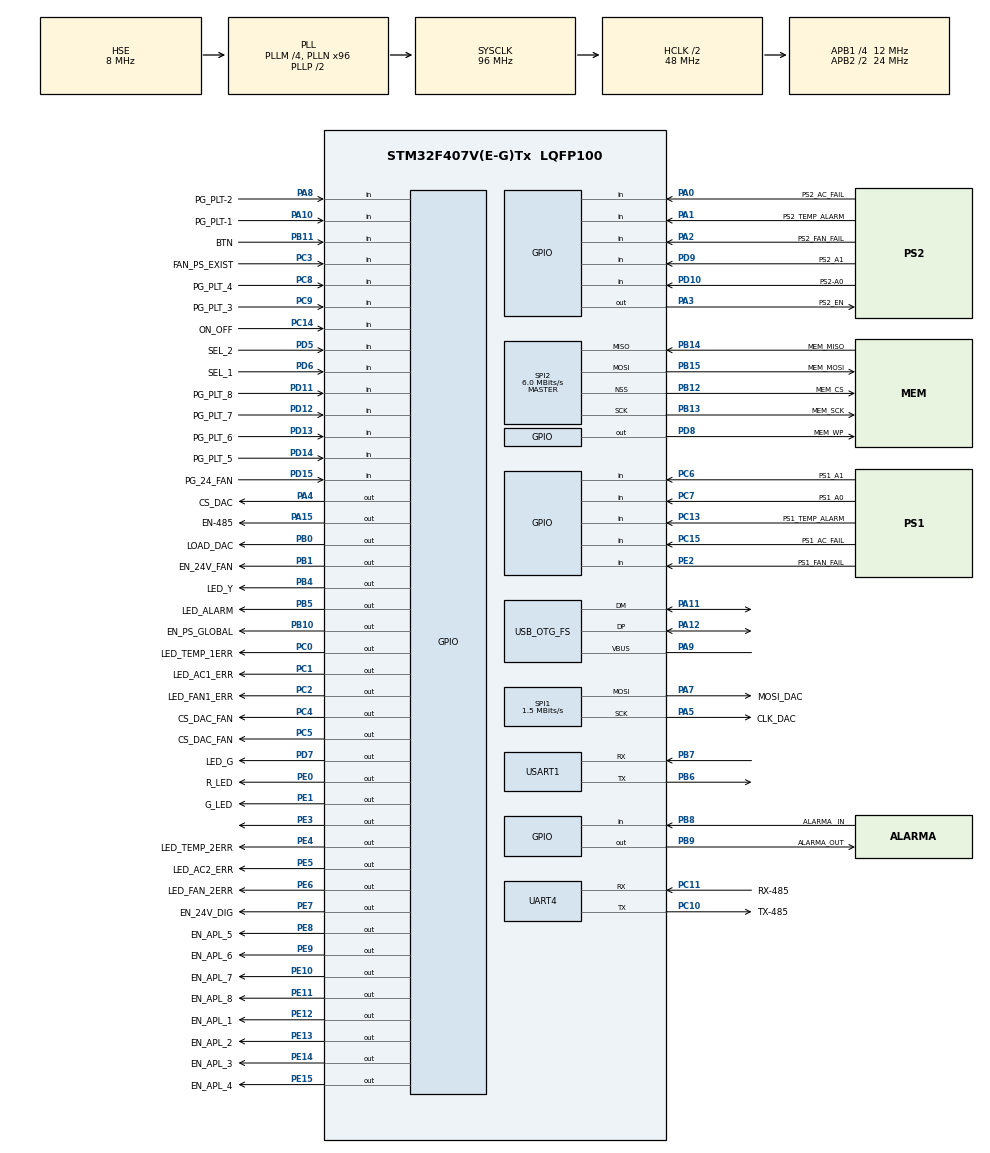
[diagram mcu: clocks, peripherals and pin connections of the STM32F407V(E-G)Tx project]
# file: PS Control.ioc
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Mcu.Family=STM32F4
Mcu.Name=STM32F407V(E-G)Tx
Mcu.Package=LQFP100
NVIC.PriorityGroup=NVIC_PRIORITYGROUP_4
NVIC.UART4_IRQn=true\:0\:0\:false\:false\:true\:true\:true\:true
NVIC.USART1_IRQn=true\:0\:0\:false\:false\:true\:true\:true\:true
PA0-WKUP.GPIO_Label=PS2_AC_FAIL
PA0-WKUP.Signal=GPIO_Input
PA1.GPIO_Label=PS2_TEMP_ALARM
PA1.GPIO_PuPd=GPIO_PULLDOWN
PA1.Signal=GPIO_Input
PA10.GPIO_Label=PG_PLT-1
PA10.GPIO_PuPd=GPIO_PULLUP
PA10.Signal=GPIO_Input
PA11.Mode=Device_Only
PA11.Signal=USB_OTG_FS_DM
PA12.Mode=Device_Only
PA12.Signal=USB_OTG_FS_DP
PA13.Signal=SYS_JTMS-SWDIO
PA14.Signal=SYS_JTCK-SWCLK
PA15.GPIO_Label=EN-485
PA15.GPIO_PuPd=GPIO_PULLDOWN
PA15.Signal=GPIO_Output
PA2.GPIO_Label=PS2_FAN_FAIL
PA2.Signal=GPIO_Input
PA3.GPIO_Label=PS2_EN
PA3.GPIO_PuPd=GPIO_PULLUP
PA3.Signal=GPIO_Output
PA4.GPIO_Label=CS_DAC
PA4.GPIO_PuPd=GPIO_PULLUP
PA4.PinState=GPIO_PIN_SET
PA4.Signal=GPIO_Output
PA5.GPIO_Label=CLK_DAC
PA5.Mode=TX_Only_Simplex_Unidirect_Master
PA5.Signal=SPI1_SCK
PA7.GPIO_Label=MOSI_DAC
PA7.Mode=TX_Only_Simplex_Unidirect_Master
PA7.Signal=SPI1_MOSI
PA8.GPIO_Label=PG_PLT-2
PA8.GPIO_PuPd=GPIO_PULLUP
PA8.Signal=GPIO_Input
PA9.Mode=Activate_VBUS
PA9.Signal=USB_OTG_FS_VBUS
PB0.GPIO_Label=LOAD_DAC
PB0.GPIO_PuPd=GPIO_PULLUP
PB0.PinState=GPIO_PIN_SET
PB0.Signal=GPIO_Output
PB1.GPIO_Label=EN_24V_FAN
PB1.GPIO_PuPd=GPIO_PULLUP
PB1.PinState=GPIO_PIN_SET
PB1.Signal=GPIO_Output
PB10.GPIO_Label=EN_PS_GLOBAL
PB10.GPIO_PuPd=GPIO_PULLUP
PB10.PinState=GPIO_PIN_SET
PB10.Signal=GPIO_Output
PB11.GPIO_Label=BTN
PB11.GPIO_PuPd=GPIO_PULLUP
PB11.Signal=GPIO_Input
PB12.GPIO_Label=MEM_CS
PB12.Mode=NSS_Signal_Hard_Output
PB12.Signal=SPI2_NSS
PB13.GPIO_Label=MEM_SCK
PB13.Mode=Full_Duplex_Master
PB13.Signal=SPI2_SCK
PB14.GPIO_Label=MEM_MISO
PB14.Mode=Full_Duplex_Master
PB14.Signal=SPI2_MISO
PB15.GPIO_Label=MEM_MOSI
PB15.Mode=Full_Duplex_Master
PB15.Signal=SPI2_MOSI
PB3.Signal=SYS_JTDO-SWO
PB4.GPIO_Label=LED_Y
PB4.PinState=GPIO_PIN_SET
PB4.Signal=GPIO_Output
PB5.GPIO_Label=LED_ALARM
PB5.PinState=GPIO_PIN_SET
PB5.Signal=GPIO_Output
PB6.Mode=Asynchronous
PB6.Signal=USART1_TX
PB7.Mode=Asynchronous
PB7.Signal=USART1_RX
PB8.GPIO_Label=ALARMA _IN
PB8.GPIO_PuPd=GPIO_PULLUP
PB8.Signal=GPIO_Input
PB9.GPIO_Label=ALARMA_OUT
PB9.GPIO_PuPd=GPIO_PULLDOWN
PB9.Signal=GPIO_Output
PC0.GPIO_Label=LED_TEMP_1ERR
PC0.PinState=GPIO_PIN_SET
PC0.Signal=GPIO_Output
PC1.GPIO_Label=LED_AC1_ERR
PC1.PinState=GPIO_PIN_SET
PC1.Signal=GPIO_Output
PC10.GPIO_Label=TX-485
PC10.Mode=Asynchronous
PC10.Signal=UART4_TX
PC11.GPIO_Label=RX-485
PC11.Mode=Asynchronous
PC11.Signal=UART4_RX
PC13-ANTI_TAMP.GPIO_Label=PS1_TEMP_ALARM
PC13-ANTI_TAMP.GPIO_PuPd=GPIO_PULLUP
PC13-ANTI_TAMP.Signal=GPIO_Input
PC14-OSC32_IN.GPIO_Label=ON_OFF
PC14-OSC32_IN.Signal=GPIO_Input
PC15-OSC32_OUT.GPIO_Label=PS1_AC_FAIL
PC15-OSC32_OUT.GPIO_PuPd=GPIO_PULLUP
PC15-OSC32_OUT.Signal=GPIO_Input
PC2.GPIO_Label=LED_FAN1_ERR
PC2.PinState=GPIO_PIN_SET
PC2.Signal=GPIO_Output
PC3.GPIO_Label=FAN_PS_EXIST
PC3.GPIO_PuPd=GPIO_PULLDOWN
PC3.Signal=GPIO_Input
PC4.GPIO_Label=CS_DAC_FAN
PC4.GPIO_PuPd=GPIO_PULLUP
PC4.PinState=GPIO_PIN_SET
PC4.Signal=GPIO_Output
PC5.GPIO_Label=CS_DAC_FAN
PC5.GPIO_PuPd=GPIO_PULLUP
PC5.PinState=GPIO_PIN_SET
PC5.Signal=GPIO_Output
PC6.GPIO_Label=PS1_A1
PC6.GPIO_PuPd=GPIO_PULLUP
PC6.Signal=GPIO_Input
PC7.GPIO_Label=PS1_A0
PC7.GPIO_PuPd=GPIO_PULLUP
PC7.Signal=GPIO_Input
PC8.GPIO_Label=PG_PLT_4
PC8.GPIO_PuPd=GPIO_PULLUP
PC8.Signal=GPIO_Input
PC9.GPIO_Label=PG_PLT_3
PC9.GPIO_PuPd=GPIO_PULLUP
PC9.Signal=GPIO_Input
PD10.GPIO_Label=PS2-A0
PD10.GPIO_PuPd=GPIO_PULLUP
PD10.Signal=GPIO_Input
PD11.GPIO_Label=PG_PLT_8
PD11.GPIO_PuPd=GPIO_PULLUP
PD11.Signal=GPIO_Input
PD12.GPIO_Label=PG_PLT_7
PD12.GPIO_PuPd=GPIO_PULLUP
PD12.Signal=GPIO_Input
PD13.GPIO_Label=PG_PLT_6
PD13.GPIO_PuPd=GPIO_PULLUP
PD13.Signal=GPIO_Input
PD14.GPIO_Label=PG_PLT_5
PD14.GPIO_PuPd=GPIO_PULLUP
PD14.Signal=GPIO_Input
PD15.GPIO_Label=PG_24_FAN
PD15.GPIO_PuPd=GPIO_PULLUP
PD15.Signal=GPIO_Input
PD5.GPIO_Label=SEL_2
PD5.GPIO_PuPd=GPIO_PULLUP
PD5.Signal=GPIO_Input
PD6.GPIO_Label=SEL_1
PD6.GPIO_PuPd=GPIO_PULLUP
PD6.Signal=GPIO_Input
PD7.GPIO_Label=LED_G
PD7.PinState=GPIO_PIN_SET
PD7.Signal=GPIO_Output
PD8.GPIO_Label=MEM_WP
PD8.GPIO_PuPd=GPIO_PULLUP
PD8.PinState=GPIO_PIN_SET
PD8.Signal=GPIO_Output
PD9.GPIO_Label=PS2_A1
PD9.GPIO_PuPd=GPIO_PULLUP
PD9.Signal=GPIO_Input
PE0.GPIO_Label=R_LED
PE0.GPIO_PuPd=GPIO_PULLDOWN
PE0.Signal=GPIO_Output
PE1.GPIO_Label=G_LED
PE1.GPIO_PuPd=GPIO_PULLDOWN
PE1.Signal=GPIO_Output
PE10.GPIO_Label=EN_APL_7
PE10.GPIO_PuPd=GPIO_PULLUP
PE10.PinState=GPIO_PIN_SET
PE10.Signal=GPIO_Output
PE11.GPIO_Label=EN_APL_8
PE11.GPIO_PuPd=GPIO_PULLUP
PE11.PinState=GPIO_PIN_SET
PE11.Signal=GPIO_Output
PE12.GPIO_Label=EN_APL_1
PE12.GPIO_PuPd=GPIO_PULLUP
PE12.PinState=GPIO_PIN_SET
PE12.Signal=GPIO_Output
PE13.GPIO_Label=EN_APL_2
PE13.GPIO_PuPd=GPIO_PULLUP
PE13.PinState=GPIO_PIN_SET
PE13.Signal=GPIO_Output
PE14.GPIO_Label=EN_APL_3
PE14.GPIO_PuPd=GPIO_PULLUP
PE14.PinState=GPIO_PIN_SET
PE14.Signal=GPIO_Output
PE15.GPIO_Label=EN_APL_4
PE15.GPIO_PuPd=GPIO_PULLUP
PE15.PinState=GPIO_PIN_SET
PE15.Signal=GPIO_Output
PE2.GPIO_Label=PS1_FAN_FAIL
PE2.Signal=GPIO_Input
PE3.Signal=GPIO_Output
PE4.GPIO_Label=LED_TEMP_2ERR
PE4.PinState=GPIO_PIN_SET
PE4.Signal=GPIO_Output
PE5.GPIO_Label=LED_AC2_ERR
PE5.PinState=GPIO_PIN_SET
PE5.Signal=GPIO_Output
PE6.GPIO_Label=LED_FAN_2ERR
PE6.PinState=GPIO_PIN_SET
PE6.Signal=GPIO_Output
PE7.GPIO_Label=EN_24V_DIG
PE7.GPIO_PuPd=GPIO_PULLUP
PE7.PinState=GPIO_PIN_SET
PE7.Signal=GPIO_Output
PE8.GPIO_Label=EN_APL_5
PE8.GPIO_PuPd=GPIO_PULLUP
PE8.PinState=GPIO_PIN_SET
PE8.Signal=GPIO_Output
PE9.GPIO_Label=EN_APL_6
PE9.GPIO_PuPd=GPIO_PULLUP
PE9.PinState=GPIO_PIN_SET
PE9.Signal=GPIO_Output
PH0-OSC_IN.Mode=HSE-External-Oscillator
PH0-OSC_IN.Signal=RCC_OSC_IN
PH1-OSC_OUT.Mode=HSE-External-Oscillator
PH1-OSC_OUT.Signal=RCC_OSC_OUT
ProjectManager.HeapSize=0x200
ProjectManager.StackSize=0x400
ProjectManager.TargetToolchain=STM32CubeIDE
RCC.48MHZClocksFreq_Value=48000000
RCC.AHBCLKDivider=RCC_SYSCLK_DIV2
RCC.AHBFreq_Value=48000000
RCC.APB1CLKDivider=RCC_HCLK_DIV4
RCC.APB1Freq_Value=12000000
RCC.APB1TimFreq_Value=24000000
RCC.APB2CLKDivider=RCC_HCLK_DIV2
RCC.APB2Freq_Value=24000000
RCC.APB2TimFreq_Value=48000000
RCC.CortexFreq_Value=48000000
RCC.HCLKFreq_Value=48000000
RCC.HSE_VALUE=8000000
RCC.HSI_VALUE=16000000
RCC.LSE_VALUE=32768
RCC.PLLM=4
RCC.PLLN=96
RCC.SYSCLKFreq_VALUE=96000000
RCC.SYSCLKSource=RCC_SYSCLKSOURCE_PLLCLK
RCC.VCOOutputFreq_Value=192000000
SPI1.BaudRatePrescaler=SPI_BAUDRATEPRESCALER_16
SPI1.CLKPhase=SPI_PHASE_2EDGE
SPI1.CalculateBaudRate=1.5 MBits/s
SPI1.Direction=SPI_DIRECTION_2LINES
SPI1.Mode=SPI_MODE_MASTER
SPI1.VirtualType=VM_MASTER
SPI2.BaudRatePrescaler=SPI_BAUDRATEPRESCALER_2
SPI2.CalculateBaudRate=6.0 MBits/s
SPI2.Direction=SPI_DIRECTION_2LINES
SPI2.Mode=SPI_MODE_MASTER
SPI2.VirtualNSS=VM_NSSHARD
SPI2.VirtualType=VM_MASTER
UART4.Parity=PARITY_EVEN
UART4.VirtualMode=Asynchronous
UART4.WordLength=WORDLENGTH_9B
USART1.VirtualMode=VM_ASYNC
USB_OTG_FS.VirtualMode=Device_Only
board=custom

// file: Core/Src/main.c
/* USER CODE BEGIN Header */
/**
  ******************************************************************************
  * @file           : main.c
  * @brief          : Main program body
  ******************************************************************************
  * @attention
  *
  * Copyright (c) 2022 STMicroelectronics.
  * All rights reserved.
  *
  * This software is licensed under terms that can be found in the LICENSE file
  * in the root directory of this software component.
  * If no LICENSE file comes with this software, it is provided AS-IS.
  *
  ******************************************************************************
  */
/* USER CODE END Header */
#include "main.h"

 SPI_HandleTypeDef hspi1;
SPI_HandleTypeDef hspi2;

UART_HandleTypeDef huart4;
UART_HandleTypeDef huart1;

PCD_HandleTypeDef hpcd_USB_OTG_FS;

void SystemClock_Config(void);
static void MX_GPIO_Init(void);
static void MX_SPI1_Init(void);
static void MX_SPI2_Init(void);
void MX_USART1_UART_Init(void);
static void MX_USB_OTG_FS_PCD_Init(void);
void MX_UART4_Init(void);

/* USER CODE BEGIN 0 */
//memory_map_t MemoryMap;
uint32_t u32TicksMain;
uint8_t ptu8data[32];
uint8_t deb1;

//Time before reset to be able to answer the frame
uint32_t u32TicksReset;

void appProtocoloSim(void);
void vars_Init(void);

void appLED_Init(void);
void appLED_Motor(void);

void APP_Accions(void);
/* USER CODE END 0 */

int main(void)
{
  /* USER CODE BEGIN 1 */
	  char buf_arr[5] = {'a','b','c','d','e'};
  /* USER CODE END 1 */

  /* MCU Configuration--------------------------------------------------------*/

  /* Reset of all peripherals, Initializes the Flash interface and the Systick. */
  HAL_Init();

  /* Configure the system clock */
  SystemClock_Config();

  /* Initialize all configured peripherals */
  MX_GPIO_Init();
  MX_SPI1_Init();
  MX_SPI2_Init();
  MX_USART1_UART_Init();
  MX_USB_OTG_FS_PCD_Init();
  MX_UART4_Init();
  /* USER CODE BEGIN 2 */
  //MemoryMap.var.cabecera_fw.board_definition.u8BoardType = 1;

  //We initialize the variables: sourcesStatus, of the protocol (MemoryMap)
  vars_Init();

  // initialize the system
  SYS_Init();

  //Initialize alarm control
  alarmsControl_init();

  // initialize the protocol
  PROTSLV_Init();

  //Initialization of the LED engine
  LED_Init();

  u32TicksMain = TICKS_GetTicks();
  //while(TICKS_DiffTicks(u32TicksMain) < 200); //wait to ensure the correct detection of the source, without this wait when the equipment started up the 2 PCB's remained as PCB1
  // We identify the PCB and the connected sources
  CTR_identif();

  // Initialize the standby module

  standbyInit();

  appSPI_init();

  appLED_Init();

  CTR_fuentes_ON_OFF_init();

  u32TicksMain = TICKS_GetTicks();

  (void)AD5676R_init();

  prtGreenLED(0);
  prtRedLED(1);

  prtGreenLED(1);
  prtRedLED(0);

  prtGreenLED(1);
  prtRedLED(1);

  /* USER CODE END 2 */

  /* Infinite loop */
  /* USER CODE BEGIN WHILE */
  while (1)
  {
//	  RS485_TRANSMIT_ENABLE(0);
//	  HAL_UART_Transmit(&huart4, buf_arr, 5, 100);
//
//		HAL_Delay(200);

      APP_Accions();
      if (fuentesStatus.alarmsOn == 1) {
          alarmsControl_motor();

      }

      //We call the LED application engine
      appLED_Motor(); //internal led of the board, identifies if it is PCB1 or 2

		//We call the engine of led 1
      LED_Motor(LED1);
		//We call the engine of led 2
      LED_Motor(LED2);

		//We call the SPI engine
      standbyMotor();

		//We call the protocol engine, slave
      PROTSLV_Motor();

      // if (prtEN_Apl1n == 0) //debug peltiers 1
      if ((standby.state == PCB_STATE_ON) || (standby.state == PCB_STATE_WAIT_FOR_STANDBY)) //faltaaa: or PCB_STATE_WAIT_FOR_STANDBY, to be able to turn them off smoothly iii TODO
      {
          appSPI_motor();
      }

      CTR_fuentes_ON_OFF_motor();

		// CTR_sources_ON_OFF();

     // appProtocolSim();
    /* USER CODE END WHILE */

  }
}

void SystemClock_Config(void)
{
  RCC_OscInitTypeDef RCC_OscInitStruct = {0};
  RCC_ClkInitTypeDef RCC_ClkInitStruct = {0};

  /** Configure the main internal regulator output voltage
  */
  __HAL_RCC_PWR_CLK_ENABLE();
  __HAL_PWR_VOLTAGESCALING_CONFIG(PWR_REGULATOR_VOLTAGE_SCALE1);

  /** Initializes the RCC Oscillators according to the specified parameters
  * in the RCC_OscInitTypeDef structure.
  */
  RCC_OscInitStruct.OscillatorType = RCC_OSCILLATORTYPE_HSE;
  RCC_OscInitStruct.HSEState = RCC_HSE_ON;
  RCC_OscInitStruct.PLL.PLLState = RCC_PLL_ON;
  RCC_OscInitStruct.PLL.PLLSource = RCC_PLLSOURCE_HSE;
  RCC_OscInitStruct.PLL.PLLM = 4;
  RCC_OscInitStruct.PLL.PLLN = 96;
  RCC_OscInitStruct.PLL.PLLP = RCC_PLLP_DIV2;
  RCC_OscInitStruct.PLL.PLLQ = 4;
  if (HAL_RCC_OscConfig(&RCC_OscInitStruct) != HAL_OK)
  {
    Error_Handler();
  }

  /** Initializes the CPU, AHB and APB buses clocks
  */
  RCC_ClkInitStruct.ClockType = RCC_CLOCKTYPE_HCLK|RCC_CLOCKTYPE_SYSCLK
                              |RCC_CLOCKTYPE_PCLK1|RCC_CLOCKTYPE_PCLK2;
  RCC_ClkInitStruct.SYSCLKSource = RCC_SYSCLKSOURCE_PLLCLK;
  RCC_ClkInitStruct.AHBCLKDivider = RCC_SYSCLK_DIV2;
  RCC_ClkInitStruct.APB1CLKDivider = RCC_HCLK_DIV4;
  RCC_ClkInitStruct.APB2CLKDivider = RCC_HCLK_DIV2;

  if (HAL_RCC_ClockConfig(&RCC_ClkInitStruct, FLASH_LATENCY_1) != HAL_OK)
  {
    Error_Handler();
  }
}

static void MX_SPI1_Init(void)
{

  /* SPI1 parameter configuration*/
  hspi1.Instance = SPI1;
  hspi1.Init.Mode = SPI_MODE_MASTER;
  hspi1.Init.Direction = SPI_DIRECTION_2LINES;
  hspi1.Init.DataSize = SPI_DATASIZE_8BIT;
  hspi1.Init.CLKPolarity = SPI_POLARITY_LOW;
  hspi1.Init.CLKPhase = SPI_PHASE_2EDGE;
  hspi1.Init.NSS = SPI_NSS_SOFT;
  hspi1.Init.BaudRatePrescaler = SPI_BAUDRATEPRESCALER_16;
  hspi1.Init.FirstBit = SPI_FIRSTBIT_MSB;
  hspi1.Init.TIMode = SPI_TIMODE_DISABLE;
  hspi1.Init.CRCCalculation = SPI_CRCCALCULATION_DISABLE;
  hspi1.Init.CRCPolynomial = 10;
  if (HAL_SPI_Init(&hspi1) != HAL_OK)
  {
    Error_Handler();
  }

}

static void MX_SPI2_Init(void)
{

  /* SPI2 parameter configuration*/
  hspi2.Instance = SPI2;
  hspi2.Init.Mode = SPI_MODE_MASTER;
  hspi2.Init.Direction = SPI_DIRECTION_2LINES;
  hspi2.Init.DataSize = SPI_DATASIZE_8BIT;
  hspi2.Init.CLKPolarity = SPI_POLARITY_LOW;
  hspi2.Init.CLKPhase = SPI_PHASE_1EDGE;
  hspi2.Init.NSS = SPI_NSS_HARD_OUTPUT;
  hspi2.Init.BaudRatePrescaler = SPI_BAUDRATEPRESCALER_2;
  hspi2.Init.FirstBit = SPI_FIRSTBIT_MSB;
  hspi2.Init.TIMode = SPI_TIMODE_DISABLE;
  hspi2.Init.CRCCalculation = SPI_CRCCALCULATION_DISABLE;
  hspi2.Init.CRCPolynomial = 10;
  if (HAL_SPI_Init(&hspi2) != HAL_OK)
  {
    Error_Handler();
  }

}

void MX_UART4_Init(void)
{

  huart4.Instance = UART4;
  huart4.Init.BaudRate = 115200;
  huart4.Init.WordLength = UART_WORDLENGTH_9B;
  huart4.Init.StopBits = UART_STOPBITS_1;
  huart4.Init.Parity = UART_PARITY_EVEN;
  huart4.Init.Mode = UART_MODE_TX_RX;
  huart4.Init.HwFlowCtl = UART_HWCONTROL_NONE;
  huart4.Init.OverSampling = UART_OVERSAMPLING_16;
  if (HAL_UART_Init(&huart4) != HAL_OK)
  {
    Error_Handler();
  }

}

void MX_USART1_UART_Init(void)
{

  huart1.Instance = USART1;
  huart1.Init.BaudRate = 115200;
  huart1.Init.WordLength = UART_WORDLENGTH_8B;
  huart1.Init.StopBits = UART_STOPBITS_1;
  huart1.Init.Parity = UART_PARITY_NONE;
  huart1.Init.Mode = UART_MODE_TX_RX;
  huart1.Init.HwFlowCtl = UART_HWCONTROL_NONE;
  huart1.Init.OverSampling = UART_OVERSAMPLING_16;
  if (HAL_UART_Init(&huart1) != HAL_OK)
  {
    Error_Handler();
  }

}

static void MX_USB_OTG_FS_PCD_Init(void)
{

  hpcd_USB_OTG_FS.Instance = USB_OTG_FS;
  hpcd_USB_OTG_FS.Init.dev_endpoints = 4;
  hpcd_USB_OTG_FS.Init.speed = PCD_SPEED_FULL;
  hpcd_USB_OTG_FS.Init.dma_enable = DISABLE;
  hpcd_USB_OTG_FS.Init.phy_itface = PCD_PHY_EMBEDDED;
  hpcd_USB_OTG_FS.Init.Sof_enable = DISABLE;
  hpcd_USB_OTG_FS.Init.low_power_enable = DISABLE;
  hpcd_USB_OTG_FS.Init.lpm_enable = DISABLE;
  hpcd_USB_OTG_FS.Init.vbus_sensing_enable = ENABLE;
  hpcd_USB_OTG_FS.Init.use_dedicated_ep1 = DISABLE;
  if (HAL_PCD_Init(&hpcd_USB_OTG_FS) != HAL_OK)
  {
    Error_Handler();
  }

}

static void MX_GPIO_Init(void)
{
  GPIO_InitTypeDef GPIO_InitStruct = {0};

  /* GPIO Ports Clock Enable */
  __HAL_RCC_GPIOE_CLK_ENABLE();
  __HAL_RCC_GPIOC_CLK_ENABLE();
  __HAL_RCC_GPIOH_CLK_ENABLE();
  __HAL_RCC_GPIOA_CLK_ENABLE();
  __HAL_RCC_GPIOB_CLK_ENABLE();
  __HAL_RCC_GPIOD_CLK_ENABLE();

  /*Configure GPIO pin Output Level */
  HAL_GPIO_WritePin(GPIOE, GPIO_PIN_3|R_LED_Pin|G_LED_Pin, GPIO_PIN_RESET);

  /*Configure GPIO pin Output Level */
  HAL_GPIO_WritePin(GPIOE, LED_TEMP_2ERR_Pin|LED_AC2_ERR_Pin|LED_FAN_2ERR_Pin|EN_24V_DIG_Pin
                          |EN_APL_5_Pin|EN_APL_6_Pin|EN_APL_7_Pin|EN_APL_8_Pin
                          |EN_APL_1_Pin|EN_APL_2_Pin|EN_APL_3_Pin|EN_APL_4_Pin, GPIO_PIN_SET);

  /*Configure GPIO pin Output Level */
  HAL_GPIO_WritePin(GPIOC, LED_TEMP_1ERR_Pin|LED_AC1_ERR_Pin|LED_FAN1_ERR_Pin|CS_DAC_FAN_Pin
                          |CS_DAC_FANC5_Pin, GPIO_PIN_SET);

  /*Configure GPIO pin Output Level */
  HAL_GPIO_WritePin(GPIOA, PS2_EN_Pin|EN_485_Pin, GPIO_PIN_RESET);

  /*Configure GPIO pin Output Level */
  HAL_GPIO_WritePin(CS_DAC_GPIO_Port, CS_DAC_Pin, GPIO_PIN_SET);

  /*Configure GPIO pin Output Level */
  HAL_GPIO_WritePin(GPIOB, LOAD_DAC_Pin|EN_24V_FAN_Pin|EN_PS_GLOBAL_Pin|LED_Y_Pin
                          |LED_ALARM_Pin, GPIO_PIN_SET);

  /*Configure GPIO pin Output Level */
  HAL_GPIO_WritePin(GPIOD, MEM_WP_Pin|LED_G_Pin, GPIO_PIN_SET);

  /*Configure GPIO pin Output Level */
  HAL_GPIO_WritePin(ALARMA_OUT_GPIO_Port, ALARMA_OUT_Pin, GPIO_PIN_RESET);

  /*Configure GPIO pin : PS1_FAN_FAIL_Pin */
  GPIO_InitStruct.Pin = PS1_FAN_FAIL_Pin;
  GPIO_InitStruct.Mode = GPIO_MODE_INPUT;
  GPIO_InitStruct.Pull = GPIO_NOPULL;
  HAL_GPIO_Init(PS1_FAN_FAIL_GPIO_Port, &GPIO_InitStruct);

  /*Configure GPIO pins : PE3 LED_TEMP_2ERR_Pin LED_AC2_ERR_Pin LED_FAN_2ERR_Pin */
  GPIO_InitStruct.Pin = GPIO_PIN_3|LED_TEMP_2ERR_Pin|LED_AC2_ERR_Pin|LED_FAN_2ERR_Pin;
  GPIO_InitStruct.Mode = GPIO_MODE_OUTPUT_PP;
  GPIO_InitStruct.Pull = GPIO_NOPULL;
  GPIO_InitStruct.Speed = GPIO_SPEED_FREQ_LOW;
  HAL_GPIO_Init(GPIOE, &GPIO_InitStruct);

  /*Configure GPIO pins : PS1_TEMP_ALARM_Pin PS1_AC_FAIL_Pin PS1_A1_Pin PS1_A0_Pin
                           PG_PLT_4_Pin PG_PLT_3_Pin */
  GPIO_InitStruct.Pin = PS1_TEMP_ALARM_Pin|PS1_AC_FAIL_Pin|PS1_A1_Pin|PS1_A0_Pin
                          |PG_PLT_4_Pin|PG_PLT_3_Pin;
  GPIO_InitStruct.Mode = GPIO_MODE_INPUT;
  GPIO_InitStruct.Pull = GPIO_PULLUP;
  HAL_GPIO_Init(GPIOC, &GPIO_InitStruct);

  /*Configure GPIO pin : ON_OFF_Pin */
  GPIO_InitStruct.Pin = ON_OFF_Pin;
  GPIO_InitStruct.Mode = GPIO_MODE_INPUT;
  GPIO_InitStruct.Pull = GPIO_NOPULL;
  HAL_GPIO_Init(ON_OFF_GPIO_Port, &GPIO_InitStruct);

  /*Configure GPIO pins : LED_TEMP_1ERR_Pin LED_AC1_ERR_Pin LED_FAN1_ERR_Pin */
  GPIO_InitStruct.Pin = LED_TEMP_1ERR_Pin|LED_AC1_ERR_Pin|LED_FAN1_ERR_Pin;
  GPIO_InitStruct.Mode = GPIO_MODE_OUTPUT_PP;
  GPIO_InitStruct.Pull = GPIO_NOPULL;
  GPIO_InitStruct.Speed = GPIO_SPEED_FREQ_LOW;
  HAL_GPIO_Init(GPIOC, &GPIO_InitStruct);

  /*Configure GPIO pin : FAN_PS_EXIST_Pin */
  GPIO_InitStruct.Pin = FAN_PS_EXIST_Pin;
  GPIO_InitStruct.Mode = GPIO_MODE_INPUT;
  GPIO_InitStruct.Pull = GPIO_PULLDOWN;
  HAL_GPIO_Init(FAN_PS_EXIST_GPIO_Port, &GPIO_InitStruct);

  /*Configure GPIO pins : PS2_AC_FAIL_Pin PS2_FAN_FAIL_Pin */
  GPIO_InitStruct.Pin = PS2_AC_FAIL_Pin|PS2_FAN_FAIL_Pin;
  GPIO_InitStruct.Mode = GPIO_MODE_INPUT;
  GPIO_InitStruct.Pull = GPIO_NOPULL;
  HAL_GPIO_Init(GPIOA, &GPIO_InitStruct);

  /*Configure GPIO pin : PS2_TEMP_ALARM_Pin */
  GPIO_InitStruct.Pin = PS2_TEMP_ALARM_Pin;
  GPIO_InitStruct.Mode = GPIO_MODE_INPUT;
  GPIO_InitStruct.Pull = GPIO_PULLDOWN;
  HAL_GPIO_Init(PS2_TEMP_ALARM_GPIO_Port, &GPIO_InitStruct);

  /*Configure GPIO pins : PS2_EN_Pin CS_DAC_Pin */
  GPIO_InitStruct.Pin = PS2_EN_Pin|CS_DAC_Pin;
  GPIO_InitStruct.Mode = GPIO_MODE_OUTPUT_PP;
  GPIO_InitStruct.Pull = GPIO_PULLUP;
  GPIO_InitStruct.Speed = GPIO_SPEED_FREQ_LOW;
  HAL_GPIO_Init(GPIOA, &GPIO_InitStruct);

  /*Configure GPIO pins : CS_DAC_FAN_Pin CS_DAC_FANC5_Pin */
  GPIO_InitStruct.Pin = CS_DAC_FAN_Pin|CS_DAC_FANC5_Pin;
  GPIO_InitStruct.Mode = GPIO_MODE_OUTPUT_PP;
  GPIO_InitStruct.Pull = GPIO_PULLUP;
  GPIO_InitStruct.Speed = GPIO_SPEED_FREQ_LOW;
  HAL_GPIO_Init(GPIOC, &GPIO_InitStruct);

  /*Configure GPIO pins : LOAD_DAC_Pin EN_24V_FAN_Pin EN_PS_GLOBAL_Pin */
  GPIO_InitStruct.Pin = LOAD_DAC_Pin|EN_24V_FAN_Pin|EN_PS_GLOBAL_Pin;
  GPIO_InitStruct.Mode = GPIO_MODE_OUTPUT_PP;
  GPIO_InitStruct.Pull = GPIO_PULLUP;
  GPIO_InitStruct.Speed = GPIO_SPEED_FREQ_LOW;
  HAL_GPIO_Init(GPIOB, &GPIO_InitStruct);

  /*Configure GPIO pins : EN_24V_DIG_Pin EN_APL_5_Pin EN_APL_6_Pin EN_APL_7_Pin
                           EN_APL_8_Pin EN_APL_1_Pin EN_APL_2_Pin EN_APL_3_Pin
                           EN_APL_4_Pin */
  GPIO_InitStruct.Pin = EN_24V_DIG_Pin|EN_APL_5_Pin|EN_APL_6_Pin|EN_APL_7_Pin
                          |EN_APL_8_Pin|EN_APL_1_Pin|EN_APL_2_Pin|EN_APL_3_Pin
                          |EN_APL_4_Pin;
  GPIO_InitStruct.Mode = GPIO_MODE_OUTPUT_PP;
  GPIO_InitStruct.Pull = GPIO_PULLUP;
  GPIO_InitStruct.Speed = GPIO_SPEED_FREQ_LOW;
  HAL_GPIO_Init(GPIOE, &GPIO_InitStruct);

  /*Configure GPIO pins : BTN_Pin ALARMA__IN_Pin */
  GPIO_InitStruct.Pin = BTN_Pin|ALARMA__IN_Pin;
  GPIO_InitStruct.Mode = GPIO_MODE_INPUT;
  GPIO_InitStruct.Pull = GPIO_PULLUP;
  HAL_GPIO_Init(GPIOB, &GPIO_InitStruct);

  /*Configure GPIO pin : MEM_WP_Pin */
  GPIO_InitStruct.Pin = MEM_WP_Pin;
  GPIO_InitStruct.Mode = GPIO_MODE_OUTPUT_PP;
  GPIO_InitStruct.Pull = GPIO_PULLUP;
  GPIO_InitStruct.Speed = GPIO_SPEED_FREQ_LOW;
  HAL_GPIO_Init(MEM_WP_GPIO_Port, &GPIO_InitStruct);

  /*Configure GPIO pins : PS2_A1_Pin PS2_A0_Pin PG_PLT_8_Pin PG_PLT_7_Pin
                           PG_PLT_6_Pin PG_PLT_5_Pin PG_24_FAN_Pin SEL_2_Pin
                           SEL_1_Pin */
  GPIO_InitStruct.Pin = PS2_A1_Pin|PS2_A0_Pin|PG_PLT_8_Pin|PG_PLT_7_Pin
                          |PG_PLT_6_Pin|PG_PLT_5_Pin|PG_24_FAN_Pin|SEL_2_Pin
                          |SEL_1_Pin;
  GPIO_InitStruct.Mode = GPIO_MODE_INPUT;
  GPIO_InitStruct.Pull = GPIO_PULLUP;
  HAL_GPIO_Init(GPIOD, &GPIO_InitStruct);

  /*Configure GPIO pins : PG_PLT_2_Pin PG_PLT_1_Pin */
  GPIO_InitStruct.Pin = PG_PLT_2_Pin|PG_PLT_1_Pin;
  GPIO_InitStruct.Mode = GPIO_MODE_INPUT;
  GPIO_InitStruct.Pull = GPIO_PULLUP;
  HAL_GPIO_Init(GPIOA, &GPIO_InitStruct);

  /*Configure GPIO pin : EN_485_Pin */
  GPIO_InitStruct.Pin = EN_485_Pin;
  GPIO_InitStruct.Mode = GPIO_MODE_OUTPUT_PP;
  GPIO_InitStruct.Pull = GPIO_PULLDOWN;
  GPIO_InitStruct.Speed = GPIO_SPEED_FREQ_LOW;
  HAL_GPIO_Init(EN_485_GPIO_Port, &GPIO_InitStruct);

  /*Configure GPIO pin : LED_G_Pin */
  GPIO_InitStruct.Pin = LED_G_Pin;
  GPIO_InitStruct.Mode = GPIO_MODE_OUTPUT_PP;
  GPIO_InitStruct.Pull = GPIO_NOPULL;
  GPIO_InitStruct.Speed = GPIO_SPEED_FREQ_LOW;
  HAL_GPIO_Init(LED_G_GPIO_Port, &GPIO_InitStruct);

  /*Configure GPIO pins : LED_Y_Pin LED_ALARM_Pin */
  GPIO_InitStruct.Pin = LED_Y_Pin|LED_ALARM_Pin;
  GPIO_InitStruct.Mode = GPIO_MODE_OUTPUT_PP;
  GPIO_InitStruct.Pull = GPIO_NOPULL;
  GPIO_InitStruct.Speed = GPIO_SPEED_FREQ_LOW;
  HAL_GPIO_Init(GPIOB, &GPIO_InitStruct);

  /*Configure GPIO pin : ALARMA_OUT_Pin */
  GPIO_InitStruct.Pin = ALARMA_OUT_Pin;
  GPIO_InitStruct.Mode = GPIO_MODE_OUTPUT_PP;
  GPIO_InitStruct.Pull = GPIO_PULLDOWN;
  GPIO_InitStruct.Speed = GPIO_SPEED_FREQ_LOW;
  HAL_GPIO_Init(ALARMA_OUT_GPIO_Port, &GPIO_InitStruct);

  /*Configure GPIO pins : R_LED_Pin G_LED_Pin */
  GPIO_InitStruct.Pin = R_LED_Pin|G_LED_Pin;
  GPIO_InitStruct.Mode = GPIO_MODE_OUTPUT_PP;
  GPIO_InitStruct.Pull = GPIO_PULLDOWN;
  GPIO_InitStruct.Speed = GPIO_SPEED_FREQ_LOW;
  HAL_GPIO_Init(GPIOE, &GPIO_InitStruct);

}

/* USER CODE BEGIN 4 */
void vars_Init(void) {

    uint8_t i;

    //fuentesStatus
    fuentesStatus.alarmsOn = 0;
    //   fuentesStatus.tempFail1 = 0;
    //   fuentesStatus.tempFail2 = 0;
    for (i = 0; i < FNT_NUM_TEMP_FAIL; i++) {
        fuentesStatus.atempFail1[i] = 0;
        fuentesStatus.atempFail2[i] = 0;
    }

    //MemoryMap
    MemoryMap.var.cabecera_fw.board_alarms.alarms = 0;
    MemoryMap.var.cabecera_fw.board_status.status = PCB_STATE_OFF;
    MemoryMap.var.cabecera_fw.u16accions = 0; //Accion idle
    MemoryMap.var.cabecera_fw.u16accioactual = 0;
    MemoryMap.var.fuentes.estadoModulos = 0;
    MemoryMap.var.fuentes.powerGoods = 0;
    MemoryMap.var.fuentes.mainStatus = MAIN_STATE_OFF;
    //4  MemoryMap.var.fuentes.modulos_ON_OFF = 0b00000000; //modules off
    MemoryMap.var.fuentes.alarma = FNT_MAIN_ALARM_NONE;

    for (i = 0; i < FNT_NUM_MODULES; i++) {
        MemoryMap.var.fuentes.aModulos_ON_OFF[i] = 0;
    }

    for (i = 0; i < MAX_NUM_SPI_CH; i++) {
        MemoryMap.var.fuentes.aVoltagePercent[i].fvalue = 0;
    }
    //  Alarms initialized on interrupts and control
}

typedef struct {
    uint8_t u8Motor;
    uint32_t u32Timer;
} appLed_t;

appLed_t appLed;

void appLED_Init(void) {
    appLed.u8Motor = 0;
}

void appLED_Motor(void) {

    switch (appLed.u8Motor) {
        case 0:
            //We capture refresh time between each protocol simulation
            appLed.u32Timer = TICKS_GetTicks();
            //We advance to the next state
            appLed.u8Motor++;
            break;

        case 1:
            //We check if the refresh time has expired
            if (TICKS_DiffTicks(appLed.u32Timer) > 1000) {

                if (identif.IdPCB == PCB1) {
                    LED_Configure(LED2, 1, 100, 100, 0); //Green LED: single flash

                } else if (identif.IdPCB == PCB2) {
                    LED_Configure(LED2, 2, 100, 100, 0); //Green LED: double flash
                }

                //Capturamos tiempo de refresco entre cada parpadeo del led
                appLed.u32Timer = TICKS_GetTicks();
                //Avanzamos al siguiente estado
                appLed.u8Motor = 0;
            }
            break;

    }
}

typedef struct {
    uint8_t u8Motor;
    uint32_t u32Timer;
} protocoloSim_t;

protocoloSim_t protocoloSim;

uint8_t debControlM;

void appProtocoloSim(void) {

    switch (protocoloSim.u8Motor) {
        case 0:
            //Capturamos tiempo de refresco entre cada simulacion de protocolo
            protocoloSim.u32Timer = TICKS_GetTicks();
            //Avanzamos al siguiente estado
            protocoloSim.u8Motor++;
            break;

        case 1:
            //Miramos si se ha cumplido el tiempo de refresco
            if (TICKS_DiffTicks(protocoloSim.u32Timer) > 2000) {
                MemoryMap.var.fuentes.mainStatus = MAIN_STATE_READY_FOR_ON;
                //4   MemoryMap.var.fuentes.modulos_ON_OFF = 0b00000010;

                MemoryMap.var.fuentes.aModulos_ON_OFF[FNT_MOD_FIXED2] = 1;

                //     debControlM=MemoryMap.var.fuentes.modulos_ON_OFF & FIXED1;
                //    debControlM=MemoryMap.var.fuentes.modulos_ON_OFF & 0b00000001;

                //Capturamos tiempo de refresco entre cada simulacion de protocolo
                protocoloSim.u32Timer = TICKS_GetTicks();
                //Avanzamos al siguiente estado
                protocoloSim.u8Motor++;
            }
            break;

        case 2:
            //Miramos si se ha cumplido el tiempo de refresco
            if (TICKS_DiffTicks(protocoloSim.u32Timer) > 2000) {
                MemoryMap.var.fuentes.aVoltagePercent[0].fvalue = 20;
                MemoryMap.var.fuentes.aVoltagePercent[1].fvalue = 40;
                MemoryMap.var.fuentes.aVoltagePercent[2].fvalue = 60;
                MemoryMap.var.fuentes.aVoltagePercent[3].fvalue = 80;

               //4 MemoryMap.var.fuentes.modulos_ON_OFF = 0b00001111;

                MemoryMap.var.fuentes.aModulos_ON_OFF[FNT_MOD_FIXED1] = 1;
                MemoryMap.var.fuentes.aModulos_ON_OFF[FNT_MOD_FIXED2] = 1;
                MemoryMap.var.fuentes.aModulos_ON_OFF[FNT_MOD_ADJUSTABLE1] = 1;
                MemoryMap.var.fuentes.aModulos_ON_OFF[FNT_MOD_ADJUSTABLE2] = 1;

                //     debControlM=MemoryMap.var.fuentes.modulos_ON_OFF & FIXED1;
                //    debControlM=MemoryMap.var.fuentes.modulos_ON_OFF & 0b00000001;

                //MemoryMap.var.fuentes.alarma=FNT_MAIN_ALARM_OFF;

                //Capturamos tiempo de refresco entre cada simulacion de protocolo
                protocoloSim.u32Timer = TICKS_GetTicks();
                //Avanzamos al siguiente estado
                protocoloSim.u8Motor++;
            }
            break;

        case 3:
            //Miramos si se ha cumplido el tiempo de refresco
            if (TICKS_DiffTicks(protocoloSim.u32Timer) > 2000) {
                //    MemoryMap.var.fuentes.modulos_ON_OFF = 0b00000000;
                //     debControlM=MemoryMap.var.fuentes.modulos_ON_OFF & FIXED1;
                //    debControlM=MemoryMap.var.fuentes.modulos_ON_OFF & 0b00000001;

                MemoryMap.var.fuentes.aVoltagePercent[0].fvalue = 20;
                MemoryMap.var.fuentes.aVoltagePercent[1].fvalue = 20;
                MemoryMap.var.fuentes.aVoltagePercent[2].fvalue = 20;
                MemoryMap.var.fuentes.aVoltagePercent[3].fvalue = 20;

                //We capture refresh time between each protocol simulation
                protocoloSim.u32Timer = TICKS_GetTicks();
                //We advance to the next state
                protocoloSim.u8Motor++;
            }
            break;

        case 4:

            //Miramos si se ha cumplido el tiempo de refresco
            if (TICKS_DiffTicks(protocoloSim.u32Timer) > 5000 && MemoryMap.var.cabecera_fw.board_status.status == PCB_STATE_WAIT_FOR_STANDBY) {
                MemoryMap.var.fuentes.mainStatus = MAIN_STATE_READY_FOR_STANDBY;
                //     debControlM=MemoryMap.var.fuentes.modulos_ON_OFF & FIXED1;
                //    debControlM=MemoryMap.var.fuentes.modulos_ON_OFF & 0b00000001;

                //We capture refresh time between each protocol simulation
                protocoloSim.u32Timer = TICKS_GetTicks();
                //We advance to the next state
                protocoloSim.u8Motor = 0;
            }
            break;

        case 5:

            break;

        default:
            break;

    }

}

void APP_Accions(void) {
    switch (MemoryMap.var.cabecera_fw.u16accions) {
        case 0:
            /*accion idle*/
            break;
        case 1:
            /* accion de reset */
            // if (MemoryMap.var.cabecera_fw.u16accioactual == 0) {
            MemoryMap.var.cabecera_fw.u16accioactual = MemoryMap.var.cabecera_fw.u16accions;
            //  LED_Configure(LED_VERMELL, 100, 80, 20);
            //  LED_Configure(LED_GROC, 100, 80, 20);
            //Tiempo para poder responder a la trama
            u32TicksReset = TICKS_GetTicks();
            MemoryMap.var.cabecera_fw.u16accions = 0;
            break;
        case 2:
            /* accion guardar config */
            //            if(MemoryMap.u8accioactual == 0)
            //            {
            //                MIFARE_ForceScan();
            //                MemoryMap.u8accioactual = MemoryMap.u8accions;
            //            }
            //            MemoryMap.u8accions = 0;
            break;

        case 3:
            /* accion standby*/

            break;

            //        case 3:
            //            /* accion cerrar EV */
            //            //Comprueba que no haya ninguna accion ejecutandose
            //            if (MemoryMap.var.cabecera_fw.u16accioactual == 0) {
            //                //Cerramos la electrovalvula
            //                evCanviaEstat(1);
            //                //Terminamos la accion
            //                MemoryMap.var.cabecera_fw.u16accions = 0;
            //
            //            }
            //            break;
            //        case 4:
            //            /* accion abrir EV */
            //            ///Comprueba que no haya ninguna accion ejecutandose
            //            if (MemoryMap.var.cabecera_fw.u16accioactual == 0) {
            //                //Abrimos la electrovalvula
            //                evCanviaEstat(0);
            //                //Terminamos la accion
            //                MemoryMap.var.cabecera_fw.u16accions = 0;
            //
            //            }
            //            break;
            //
            //        case 5:
            //            /* accion abrir EV temporizada */
            //            //Comprueba que no haya ninguna accion ejecutandose
            //            if (MemoryMap.var.cabecera_fw.u16accioactual == 0) {
            //                evOnTemp(MemoryMap.var.complementos.tiempoEV_ON.u32value); //faltaa: cambiar por variable memoryMap
            //                //Terminamos la accion
            //                MemoryMap.var.cabecera_fw.u16accions = 0;
            //
            //            }
            //
            //
            //            break;

        default:
            MemoryMap.var.cabecera_fw.u16accions = 0;
            break;
    }

    switch (MemoryMap.var.cabecera_fw.u16accioactual) {
        case 0:
            /*accion idle*/
            break;
        case 1:
            /* accion de reset */
//            if (TICKS_DiffTicks(u32TicksReset) > 500) {
//                Reset();
//            }
            break;
        case 2:
            /* accion guardar config */

            //            if(MIFARE_GetScanStatus() == 0)
            //            {
            //                MemoryMap.u8accioactual = 0;
            //            }
            //            else
            //            {
            //
            //            }
            break;

        case 3:
            /* action close EV */
            break;

        case 4:
            /* action open EV */
            break;

        case 5:
            /* accion abrir EV temporizada */
            break;
        default:
            MemoryMap.var.cabecera_fw.u16accioactual = 0;
            break;
    }
}

/* USER CODE END 4 */

void Error_Handler(void)
{
  __disable_irq();
  while (1)
  {
  }
}
